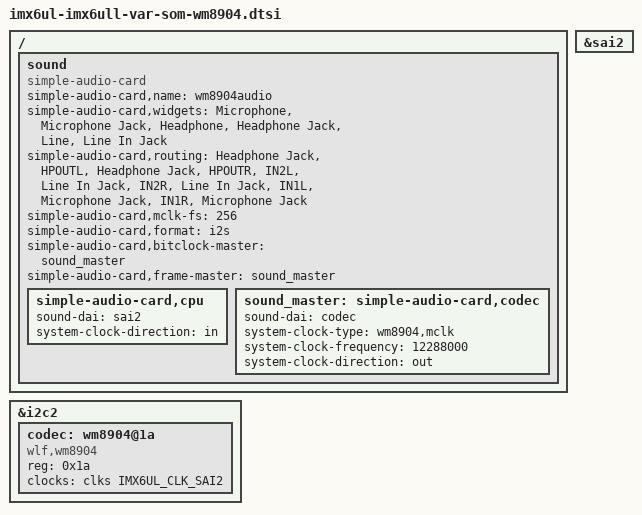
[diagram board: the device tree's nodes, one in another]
/*
 * Copyright (C) 2024 Variscite Ltd. - http://www.variscite.com
 *
 * This program is free software; you can redistribute it and/or modify
 * it under the terms of the GNU General Public License version 2 as
 * published by the Free Software Foundation.
 */

/ {
	sound {
		compatible = "simple-audio-card";
		simple-audio-card,name = "wm8904audio";
		simple-audio-card,widgets =
			"Microphone", "Microphone Jack",
			"Headphone", "Headphone Jack",
			"Line", "Line In Jack";
		simple-audio-card,routing =
			"Headphone Jack", "HPOUTL",
			"Headphone Jack", "HPOUTR",
			"IN2L", "Line In Jack",
			"IN2R", "Line In Jack",
			"IN1L", "Microphone Jack",
			"IN1R", "Microphone Jack";
		simple-audio-card,mclk-fs = <256>;
		simple-audio-card,format = "i2s";
		simple-audio-card,bitclock-master = <&sound_master>;
		simple-audio-card,frame-master = <&sound_master>;

		simple-audio-card,cpu {
			sound-dai = <&sai2>;
			system-clock-direction = "in";
		};

		sound_master: simple-audio-card,codec {
			sound-dai = <&codec>;
			system-clock-type = "wm8904,mclk";
			system-clock-frequency = <12288000>;
			system-clock-direction = "out";
		};
	};
};

&i2c2 {
	codec: wm8904@1a {
		compatible = "wlf,wm8904";
		#sound-dai-cells = <0>;
		reg = <0x1a>;
		clocks = <&clks IMX6UL_CLK_SAI2>;
		clock-names = "mclk";
		status = "okay";
	};
};

&sai2 {
	#sound-dai-cells = <0>;
};
